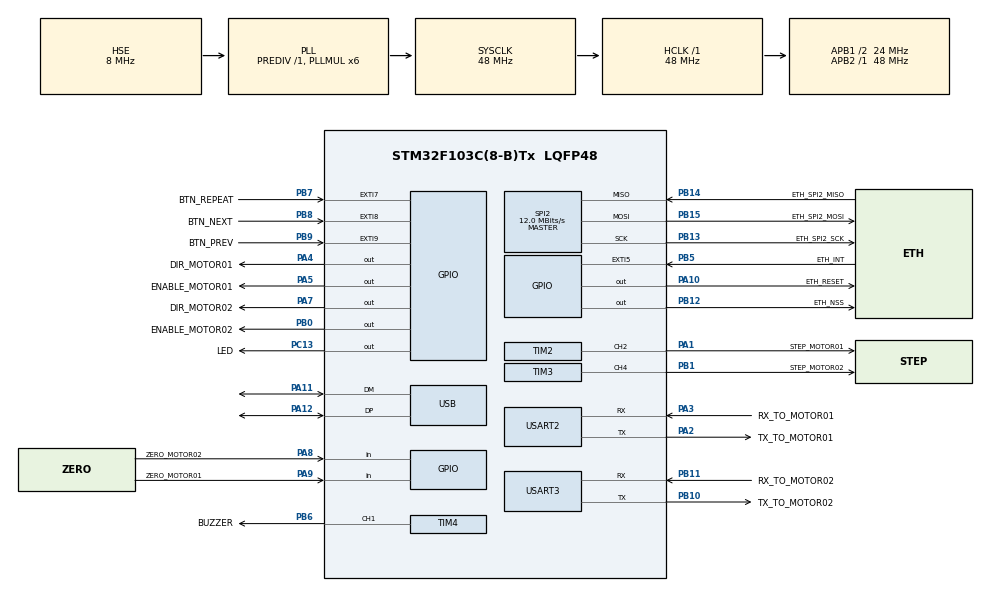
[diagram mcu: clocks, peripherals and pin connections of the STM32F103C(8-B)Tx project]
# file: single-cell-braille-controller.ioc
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Mcu.Family=STM32F1
Mcu.Name=STM32F103C(8-B)Tx
Mcu.Package=LQFP48
NVIC.EXTI9_5_IRQn=true\:0\:0\:false\:false\:true\:true\:true\:true
NVIC.PriorityGroup=NVIC_PRIORITYGROUP_4
NVIC.TIM2_IRQn=true\:0\:0\:false\:false\:true\:true\:true\:true
NVIC.TIM3_IRQn=true\:0\:0\:false\:false\:true\:true\:true\:true
NVIC.USART2_IRQn=true\:0\:0\:false\:false\:true\:true\:true\:true
NVIC.USART3_IRQn=true\:0\:0\:false\:false\:true\:true\:true\:true
NVIC.USB_LP_CAN1_RX0_IRQn=true\:0\:0\:false\:false\:true\:false\:true\:true
PA1.GPIO_Label=STEP_MOTOR01
PA1.Signal=S_TIM2_CH2
PA10.GPIO_Label=ETH_RESET
PA10.GPIO_Speed=GPIO_SPEED_FREQ_HIGH
PA10.PinState=GPIO_PIN_SET
PA10.Signal=GPIO_Output
PA11.Mode=Device
PA11.Signal=USB_DM
PA12.Mode=Device
PA12.Signal=USB_DP
PA13.Mode=Serial_Wire
PA13.Signal=SYS_JTMS-SWDIO
PA14.Mode=Serial_Wire
PA14.Signal=SYS_JTCK-SWCLK
PA2.GPIO_Label=TX_TO_MOTOR01
PA2.Mode=Asynchronous
PA2.Signal=USART2_TX
PA3.GPIO_Label=RX_TO_MOTOR01
PA3.Mode=Asynchronous
PA3.Signal=USART2_RX
PA4.GPIO_Label=DIR_MOTOR01
PA4.Signal=GPIO_Output
PA5.GPIO_Label=ENABLE_MOTOR01
PA5.GPIO_PuPd=GPIO_PULLUP
PA5.GPIO_Speed=GPIO_SPEED_FREQ_MEDIUM
PA5.PinState=GPIO_PIN_SET
PA5.Signal=GPIO_Output
PA7.GPIO_Label=DIR_MOTOR02
PA7.Signal=GPIO_Output
PA8.GPIO_Label=ZERO_MOTOR02
PA8.GPIO_PuPd=GPIO_PULLDOWN
PA8.Signal=GPIO_Input
PA9.GPIO_Label=ZERO_MOTOR01
PA9.GPIO_PuPd=GPIO_PULLDOWN
PA9.Signal=GPIO_Input
PB0.GPIO_Label=ENABLE_MOTOR02
PB0.GPIO_PuPd=GPIO_PULLUP
PB0.GPIO_Speed=GPIO_SPEED_FREQ_MEDIUM
PB0.PinState=GPIO_PIN_SET
PB0.Signal=GPIO_Output
PB1.GPIO_Label=STEP_MOTOR02
PB1.Signal=S_TIM3_CH4
PB10.GPIO_Label=TX_TO_MOTOR02
PB10.Mode=Asynchronous
PB10.Signal=USART3_TX
PB11.GPIO_Label=RX_TO_MOTOR02
PB11.Mode=Asynchronous
PB11.Signal=USART3_RX
PB12.GPIO_Label=ETH_NSS
PB12.GPIO_PuPd=GPIO_PULLUP
PB12.GPIO_Speed=GPIO_SPEED_FREQ_HIGH
PB12.PinState=GPIO_PIN_SET
PB12.Signal=GPIO_Output
PB13.GPIO_Label=ETH_SPI2_SCK
PB13.Mode=Full_Duplex_Master
PB13.Signal=SPI2_SCK
PB14.GPIO_Label=ETH_SPI2_MISO
PB14.Mode=Full_Duplex_Master
PB14.Signal=SPI2_MISO
PB15.GPIO_Label=ETH_SPI2_MOSI
PB15.Mode=Full_Duplex_Master
PB15.Signal=SPI2_MOSI
PB5.GPIO_Label=ETH_INT
PB5.GPIO_ModeDefaultEXTI=GPIO_MODE_IT_FALLING
PB5.GPIO_PuPd=GPIO_PULLUP
PB5.Signal=GPXTI5
PB6.GPIO_Label=BUZZER
PB6.Signal=S_TIM4_CH1
PB7.GPIO_Label=BTN_REPEAT
PB7.GPIO_ModeDefaultEXTI=GPIO_MODE_IT_FALLING
PB7.GPIO_PuPd=GPIO_PULLUP
PB7.Signal=GPXTI7
PB8.GPIO_Label=BTN_NEXT
PB8.GPIO_ModeDefaultEXTI=GPIO_MODE_IT_FALLING
PB8.GPIO_PuPd=GPIO_PULLUP
PB8.Signal=GPXTI8
PB9.GPIO_Label=BTN_PREV
PB9.GPIO_ModeDefaultEXTI=GPIO_MODE_IT_FALLING
PB9.GPIO_PuPd=GPIO_PULLUP
PB9.Signal=GPXTI9
PC13-TAMPER-RTC.GPIO_Label=LED
PC13-TAMPER-RTC.Signal=GPIO_Output
PD0-OSC_IN.Mode=HSE-External-Oscillator
PD0-OSC_IN.Signal=RCC_OSC_IN
PD1-OSC_OUT.Mode=HSE-External-Oscillator
PD1-OSC_OUT.Signal=RCC_OSC_OUT
ProjectManager.HeapSize=0x200
ProjectManager.StackSize=0x400
ProjectManager.TargetToolchain=CMake
RCC.AHBFreq_Value=48000000
RCC.APB1CLKDivider=RCC_HCLK_DIV2
RCC.APB1Freq_Value=24000000
RCC.APB1TimFreq_Value=48000000
RCC.APB2Freq_Value=48000000
RCC.APB2TimFreq_Value=48000000
RCC.HCLKFreq_Value=48000000
RCC.PLLMUL=RCC_PLL_MUL6
RCC.PLLSourceVirtual=RCC_PLLSOURCE_HSE
RCC.SYSCLKFreq_VALUE=48000000
RCC.SYSCLKSource=RCC_SYSCLKSOURCE_PLLCLK
RCC.USBFreq_Value=48000000
SH.S_TIM2_CH2.0=TIM2_CH2,PWM Generation2 CH2
SH.S_TIM3_CH4.0=TIM3_CH4,PWM Generation4 CH4
SH.S_TIM4_CH1.0=TIM4_CH1,PWM Generation1 CH1
SPI2.BaudRatePrescaler=SPI_BAUDRATEPRESCALER_2
SPI2.CalculateBaudRate=12.0 MBits/s
SPI2.Direction=SPI_DIRECTION_2LINES
SPI2.Mode=SPI_MODE_MASTER
SPI2.VirtualType=VM_MASTER
TIM2.AutoReloadPreload=TIM_AUTORELOAD_PRELOAD_ENABLE
TIM2.Channel-PWM\ Generation2\ CH2=TIM_CHANNEL_2
TIM2.Period=999
TIM2.Prescaler=47
TIM2.Pulse-PWM\ Generation2\ CH2=500
TIM3.AutoReloadPreload=TIM_AUTORELOAD_PRELOAD_ENABLE
TIM3.Channel-PWM\ Generation4\ CH4=TIM_CHANNEL_4
TIM3.Period=999
TIM3.Prescaler=47
TIM3.Pulse-PWM\ Generation4\ CH4=500
TIM4.Channel-PWM\ Generation1\ CH1=TIM_CHANNEL_1
TIM4.Period=1000
TIM4.Prescaler=47
TIM4.Pulse-PWM\ Generation1\ CH1=500
USART2.VirtualMode=VM_ASYNC
USART3.VirtualMode=VM_ASYNC
USB_DEVICE.CLASS_NAME_FS=CDC
USB_DEVICE.VirtualMode=Cdc
USB_DEVICE.VirtualModeFS=Cdc_FS
VP_TIM2_VS_ClockSourceINT.Mode=Internal
VP_TIM3_VS_ClockSourceINT.Mode=Internal
VP_TIM4_VS_ClockSourceINT.Mode=Internal
VP_USB_DEVICE_VS_USB_DEVICE_CDC_FS.Mode=CDC_FS
board=custom

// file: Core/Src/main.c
/* USER CODE BEGIN Header */
/**
 ******************************************************************************
 * @file           : main.c
 * @brief          : Main program body
 ******************************************************************************
 * @attention
 *
 * Copyright (c) 2026 STMicroelectronics.
 * All rights reserved.
 *
 * This software is licensed under terms that can be found in the LICENSE file
 * in the root directory of this software component.
 * If no LICENSE file comes with this software, it is provided AS-IS.
 *
 ******************************************************************************
 */
/* USER CODE END Header */
#include "main.h"
#include "spi.h"
#include "tim.h"
#include "usart.h"
#include "usb_device.h"
#include "gpio.h"

/* USER CODE BEGIN Includes */
#include "app_main.h"
/* USER CODE END Includes */

void SystemClock_Config(void);

int main(void)
{

  /* MCU Configuration--------------------------------------------------------*/

  /* Reset of all peripherals, Initializes the Flash interface and the Systick. */
  HAL_Init();

  /* Configure the system clock */
  SystemClock_Config();

  /* Initialize all configured peripherals */
  MX_GPIO_Init();
  MX_USART2_UART_Init();
  MX_USART3_UART_Init();
  MX_TIM2_Init();
  MX_TIM3_Init();
  MX_USB_DEVICE_Init();
  MX_SPI2_Init();
  MX_TIM4_Init();
  /* USER CODE BEGIN 2 */
  App_init(&huart2, &huart3, &htim2, &htim3, &htim4, &hspi2);
  /* USER CODE END 2 */

  /* Infinite loop */
  while (1) {

    /* USER CODE BEGIN 3 */
    App_run();
  }
  /* USER CODE END 3 */
}

void SystemClock_Config(void)
{
  RCC_OscInitTypeDef RCC_OscInitStruct = {0};
  RCC_ClkInitTypeDef RCC_ClkInitStruct = {0};
  RCC_PeriphCLKInitTypeDef PeriphClkInit = {0};

  /** Initializes the RCC Oscillators according to the specified parameters
  * in the RCC_OscInitTypeDef structure.
  */
  RCC_OscInitStruct.OscillatorType = RCC_OSCILLATORTYPE_HSE;
  RCC_OscInitStruct.HSEState = RCC_HSE_ON;
  RCC_OscInitStruct.HSEPredivValue = RCC_HSE_PREDIV_DIV1;
  RCC_OscInitStruct.HSIState = RCC_HSI_ON;
  RCC_OscInitStruct.PLL.PLLState = RCC_PLL_ON;
  RCC_OscInitStruct.PLL.PLLSource = RCC_PLLSOURCE_HSE;
  RCC_OscInitStruct.PLL.PLLMUL = RCC_PLL_MUL6;
  if (HAL_RCC_OscConfig(&RCC_OscInitStruct) != HAL_OK)
  {
    Error_Handler();
  }

  /** Initializes the CPU, AHB and APB buses clocks
  */
  RCC_ClkInitStruct.ClockType = RCC_CLOCKTYPE_HCLK|RCC_CLOCKTYPE_SYSCLK
                              |RCC_CLOCKTYPE_PCLK1|RCC_CLOCKTYPE_PCLK2;
  RCC_ClkInitStruct.SYSCLKSource = RCC_SYSCLKSOURCE_PLLCLK;
  RCC_ClkInitStruct.AHBCLKDivider = RCC_SYSCLK_DIV1;
  RCC_ClkInitStruct.APB1CLKDivider = RCC_HCLK_DIV2;
  RCC_ClkInitStruct.APB2CLKDivider = RCC_HCLK_DIV1;

  if (HAL_RCC_ClockConfig(&RCC_ClkInitStruct, FLASH_LATENCY_1) != HAL_OK)
  {
    Error_Handler();
  }
  PeriphClkInit.PeriphClockSelection = RCC_PERIPHCLK_USB;
  PeriphClkInit.UsbClockSelection = RCC_USBCLKSOURCE_PLL;
  if (HAL_RCCEx_PeriphCLKConfig(&PeriphClkInit) != HAL_OK)
  {
    Error_Handler();
  }
}

void Error_Handler(void)
{
  __disable_irq();
  while (1) {
  }
}
#ifdef USE_FULL_ASSERT
/**
  * @brief  Reports the name of the source file and the source line number
  *         where the assert_param error has occurred.
  * @param  file: pointer to the source file name
  * @param  line: assert_param error line source number
  * @retval None
  */
void assert_failed(uint8_t *file, uint32_t line)
{
  /* USER CODE BEGIN 6 */
  /* User can add his own implementation to report the file name and line
     number, ex: printf("Wrong parameters value: file %s on line %d\r\n", file,
     line) */
  /* USER CODE END 6 */
}
#endif /* USE_FULL_ASSERT */
